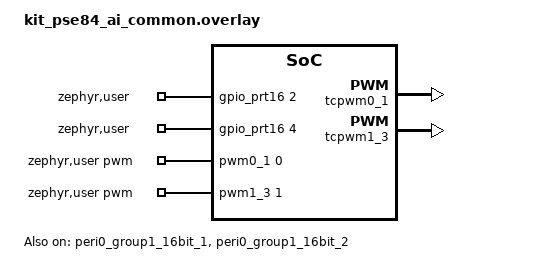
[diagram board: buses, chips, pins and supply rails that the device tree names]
/*
 * Copyright (c) 2026 Infineon Technologies AG,
 * or an affiliate of Infineon Technologies AG.
 *
 * SPDX-License-Identifier: Apache-2.0
 */

#include <zephyr/dt-bindings/pwm/pwm.h>
#include <zephyr/dt-bindings/pwm/pwm_ifx_tcpwm.h>

/ {
	zephyr,user {
		pwms = <&pwm0_1 0 PWM_MSEC(6) (PWM_POLARITY_NORMAL | PWM_IFX_TCPWM_OUTPUT_HIGHZ)>,
		       <&pwm1_3 1 PWM_MSEC(6) (PWM_POLARITY_NORMAL | PWM_IFX_TCPWM_OUTPUT_HIGHZ)>;
		gpios = <&gpio_prt16 2 GPIO_ACTIVE_HIGH>,
			<&gpio_prt16 4 GPIO_ACTIVE_HIGH>;
	};
};

&tcpwm0_1 {
	status = "okay";

	pwm0_1: pwm0_1 {
		status = "okay";
		clocks = <&peri0_group1_16bit_1>;
		pinctrl-0 = <&p16_1_pwm0_1>;
		pinctrl-names = "default";
	};
};

&peri0_group1_16bit_1 {
	status = "okay";
	clock-div = <9600>;
};

&tcpwm1_3 {
	status = "okay";

	pwm1_3: pwm1_3 {
		status = "okay";
		clocks = <&peri0_group1_16bit_2>;
		pinctrl-0 = <&p16_3_pwm1_3>;
		pinctrl-names = "default";
	};
};

&peri0_group1_16bit_2 {
	status = "okay";
	clock-div = <9600>;
};

&pinctrl {
	p16_1_pwm0_1: p16_1_pwm0_1 {
		drive-push-pull;
	};

	p16_3_pwm1_3: p16_3_pwm1_3 {
		drive-push-pull;
	};
};
